# HDSC_HC32L073KATA register map
Vendor: HDSC Co.Ltd; Series: ARMCM0P; File version: 1.2
CPU: CM0 r0p0, little endian, no MPU, no FPU, 3 interrupt priority bits
Registers are 32-bit, read-write, reset 0x0 unless marked. A register's access mark holds for its fields unless they carry their own. Offsets are from the block's base; [hi:lo] are bit positions.

## RAM
Base 0x40020400
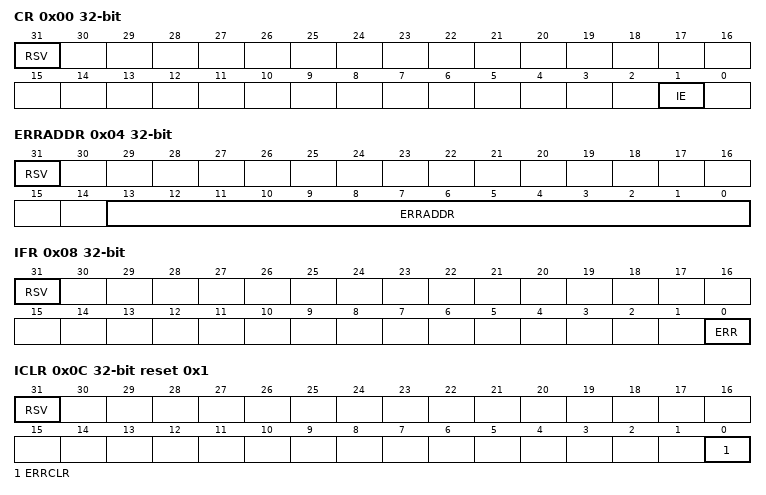
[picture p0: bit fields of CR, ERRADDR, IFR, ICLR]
0x00 CR (reset mask 0x3)
  [31] RSV, [1] IE
0x04 ERRADDR ro (reset mask 0x1FFF)
  [31] RSV rw, [13:0] ERRADDR
0x08 IFR ro (reset mask 0x1)
  [31] RSV, [0] ERR
0x0C ICLR wo reset 0x1 (reset mask 0x1)
  [31] RSV ro, [0] ERRCLR

## RESET
Base 0x4000201C
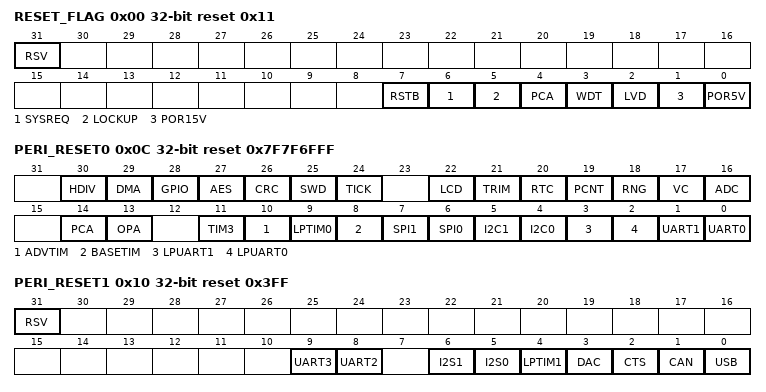
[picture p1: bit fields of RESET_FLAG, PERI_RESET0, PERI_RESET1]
0x00 RESET_FLAG reset 0x11 (reset mask 0xFF)
  [31] RSV, [7] RSTB, [6] SYSREQ, [5] LOCKUP, [4] PCA, [3] WDT, [2] LVD, [1] POR15V, [0] POR5V
0x0C PERI_RESET0 reset 0x7F7F6FFF
  [30] HDIV, [29] DMA, [28] GPIO, [27] AES, [26] CRC, [25] SWD, [24] TICK, [22] LCD, [21] TRIM, [20] RTC, [19] PCNT, [18] RNG, [17] VC, [16] ADC, [14] PCA, [13] OPA, [11] TIM3, [10] ADVTIM, [9] LPTIM0, [8] BASETIM, [7] SPI1, [6] SPI0, [5] I2C1, [4] I2C0, [3] LPUART1, [2] LPUART0, [1] UART1, [0] UART0
0x10 PERI_RESET1 reset 0x3FF (reset mask 0x3FFF)
  [31] RSV, [9] UART3, [8] UART2, [6] I2S1, [5] I2S0, [4] LPTIM1, [3] DAC, [2] CTS, [1] CAN, [0] USB

## RTC
Base 0x40001400
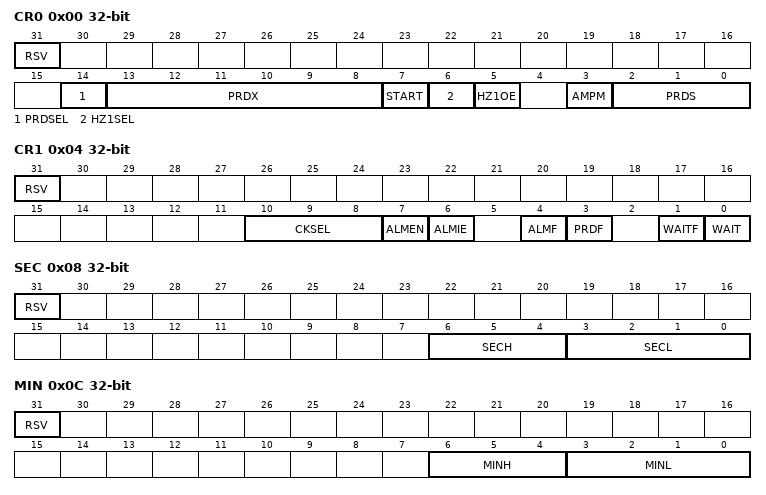
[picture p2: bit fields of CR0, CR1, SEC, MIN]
0x00 CR0 (reset mask 0x7FEF)
  [31] RSV, [14] PRDSEL, [13:8] PRDX, [7] START, [6] HZ1SEL, [5] HZ1OE, [3] AMPM, [2:0] PRDS
0x04 CR1 (reset mask 0x7FB)
  [31] RSV, [10:8] CKSEL, [7] ALMEN, [6] ALMIE, [4] ALMF, [3] PRDF, [1] WAITF, [0] WAIT
0x08 SEC (reset mask 0x7F)
  [31] RSV, [6:4] SECH, [3:0] SECL
0x0C MIN (reset mask 0x7F)
  [31] RSV, [6:4] MINH, [3:0] MINL
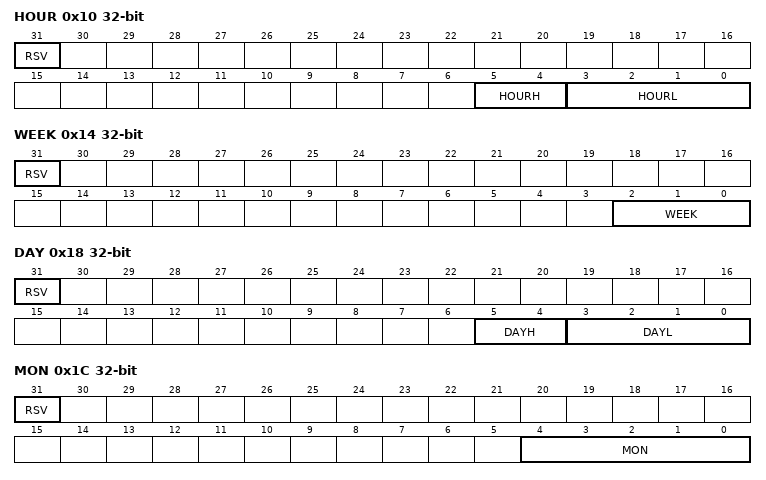
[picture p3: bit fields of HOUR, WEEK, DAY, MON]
0x10 HOUR (reset mask 0x7F)
  [31] RSV, [5:4] HOURH, [3:0] HOURL
0x14 WEEK (reset mask 0x7)
  [31] RSV, [2:0] WEEK
0x18 DAY (reset mask 0x3F)
  [31] RSV, [5:4] DAYH, [3:0] DAYL
0x1C MON (reset mask 0x1F)
  [31] RSV, [4:0] MON
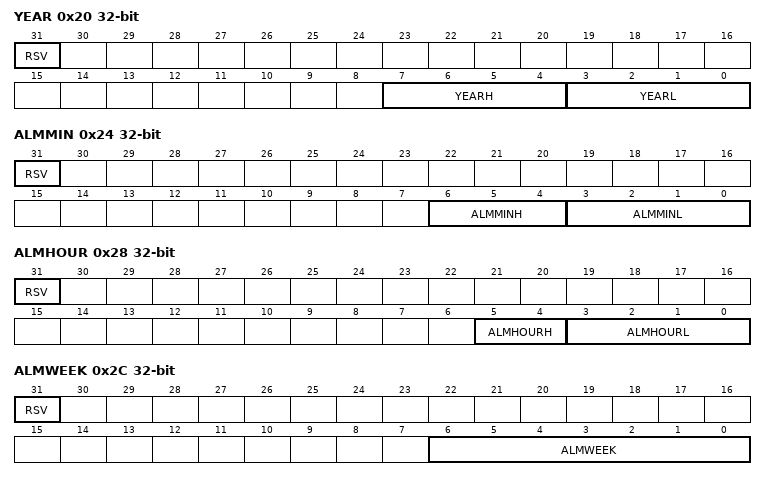
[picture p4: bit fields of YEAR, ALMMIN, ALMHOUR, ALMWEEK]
0x20 YEAR (reset mask 0xFF)
  [31] RSV, [7:4] YEARH, [3:0] YEARL
0x24 ALMMIN (reset mask 0x7F)
  [31] RSV, [6:4] ALMMINH, [3:0] ALMMINL
0x28 ALMHOUR (reset mask 0x3F)
  [31] RSV, [5:4] ALMHOURH, [3:0] ALMHOURL
0x2C ALMWEEK (reset mask 0x7F)
  [31] RSV, [6:0] ALMWEEK
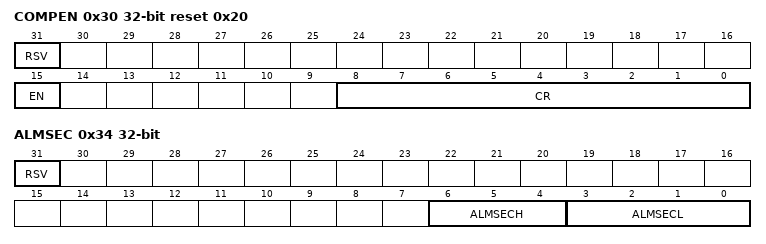
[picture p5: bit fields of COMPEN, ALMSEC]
0x30 COMPEN reset 0x20 (reset mask 0x81FF)
  [31] RSV, [15] EN, [8:0] CR
0x34 ALMSEC (reset mask 0xFF)
  [31] RSV, [6:4] ALMSECH, [3:0] ALMSECL

## SPI0 — desc SPI
Base 0x40000800
Same registers: SPI1 0x40004800
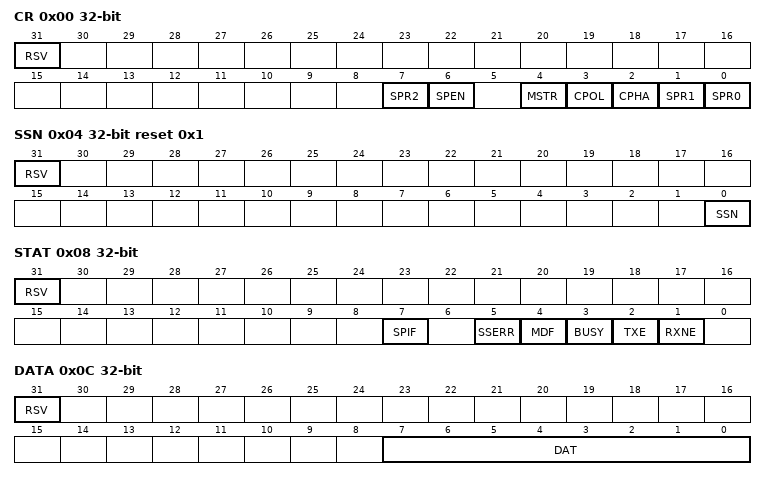
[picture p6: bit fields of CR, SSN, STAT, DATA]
0x00 CR (reset mask 0xDF)
  [31] RSV, [7] SPR2, [6] SPEN, [4] MSTR, [3] CPOL, [2] CPHA, [1] SPR1, [0] SPR0
0x04 SSN reset 0x1 (reset mask 0x1)
  [31] RSV, [0] SSN
0x08 STAT ro (reset mask 0xBE)
  [31] RSV rw, [7] SPIF, [5] SSERR, [4] MDF, [3] BUSY, [2] TXE, [1] RXNE
0x0C DATA (reset mask 0xFF)
  [31] RSV, [7:0] DAT
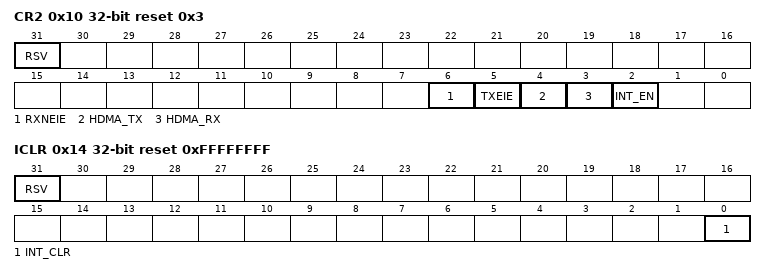
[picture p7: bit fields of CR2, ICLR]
0x10 CR2 reset 0x3 (reset mask 0x7C)
  [31] RSV, [6] RXNEIE, [5] TXEIE, [4] HDMA_TX, [3] HDMA_RX, [2] INT_EN
0x14 ICLR wo reset 0xFFFFFFFF (reset mask 0x1)
  [31] RSV rw, [0] INT_CLR

## SYSCTRL
Base 0x40002000
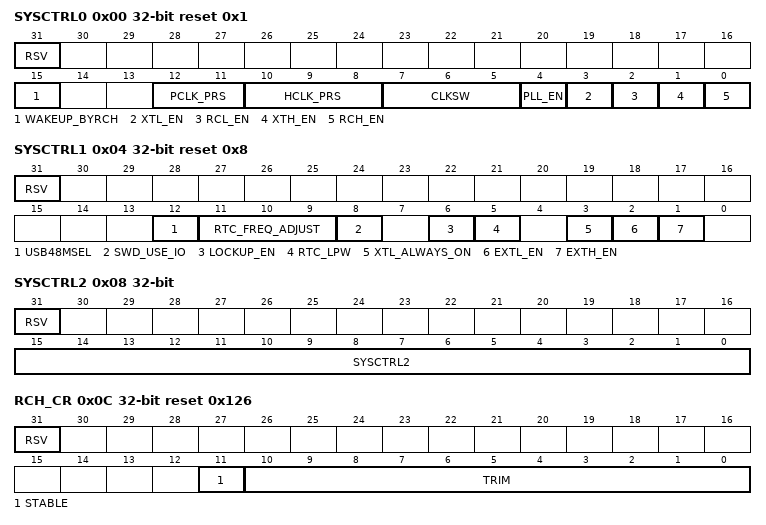
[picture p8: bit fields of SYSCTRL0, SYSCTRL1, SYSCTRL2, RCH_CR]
0x00 SYSCTRL0 reset 0x1 (reset mask 0x9FFF)
  [31] RSV, [15] WAKEUP_BYRCH, [12:11] PCLK_PRS, [10:8] HCLK_PRS, [7:5] CLKSW, [4] PLL_EN, [3] XTL_EN, [2] RCL_EN, [1] XTH_EN, [0] RCH_EN
0x04 SYSCTRL1 reset 0x8 (reset mask 0xF7E)
  [31] RSV, [12] USB48MSEL, [11:9] RTC_FREQ_ADJUST, [8] SWD_USE_IO, [6] LOCKUP_EN, [5] RTC_LPW, [3] XTL_ALWAYS_ON, [2] EXTL_EN, [1] EXTH_EN
0x08 SYSCTRL2 wo (reset mask 0xFFFF)
  [31] RSV rw, [15:0] SYSCTRL2
0x0C RCH_CR reset 0x126 (reset mask 0xFFF)
  [31] RSV, [11] STABLE ro, [10:0] TRIM
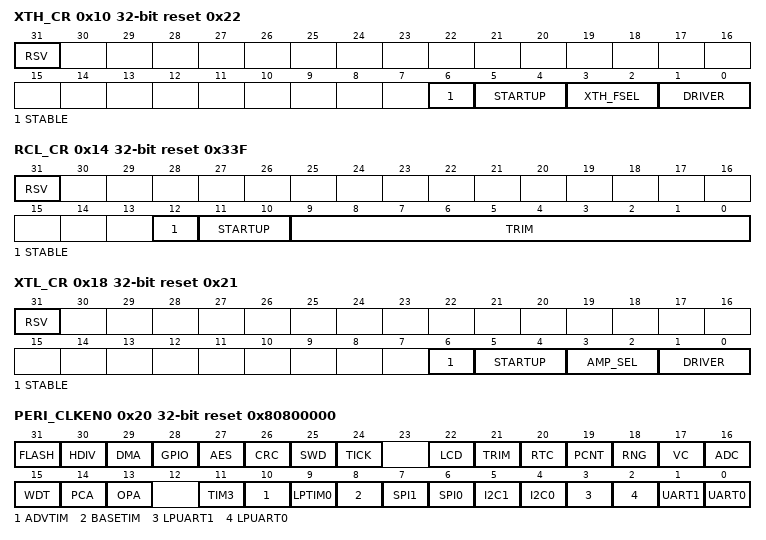
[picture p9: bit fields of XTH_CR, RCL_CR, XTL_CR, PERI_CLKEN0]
0x10 XTH_CR reset 0x22 (reset mask 0x7F)
  [31] RSV, [6] STABLE ro, [5:4] STARTUP, [3:2] XTH_FSEL, [1:0] DRIVER
0x14 RCL_CR reset 0x33F (reset mask 0x1FFF)
  [31] RSV, [12] STABLE ro, [11:10] STARTUP, [9:0] TRIM
0x18 XTL_CR reset 0x21 (reset mask 0x7F)
  [31] RSV, [6] STABLE ro, [5:4] STARTUP, [3:2] AMP_SEL, [1:0] DRIVER
0x20 PERI_CLKEN0 reset 0x80800000
  [31] FLASH, [30] HDIV, [29] DMA, [28] GPIO, [27] AES, [26] CRC, [25] SWD, [24] TICK, [22] LCD, [21] TRIM, [20] RTC, [19] PCNT, [18] RNG, [17] VC, [16] ADC, [15] WDT, [14] PCA, [13] OPA, [11] TIM3, [10] ADVTIM, [9] LPTIM0, [8] BASETIM, [7] SPI1, [6] SPI0, [5] I2C1, [4] I2C0, [3] LPUART1, [2] LPUART0, [1] UART1, [0] UART0
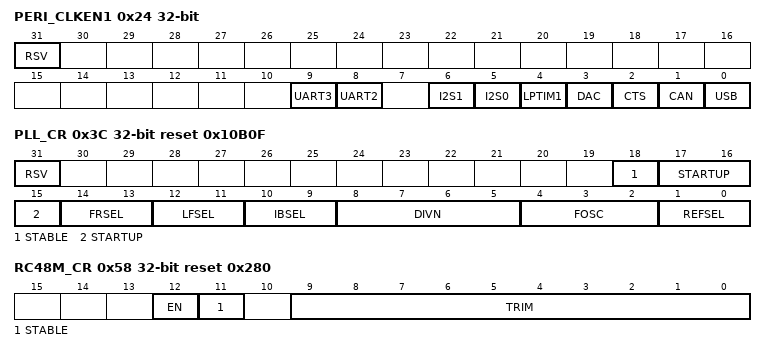
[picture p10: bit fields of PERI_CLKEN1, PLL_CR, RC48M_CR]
0x24 PERI_CLKEN1 (reset mask 0xFFF)
  [31] RSV, [9] UART3, [8] UART2, [6] I2S1, [5] I2S0, [4] LPTIM1, [3] DAC, [2] CTS, [1] CAN, [0] USB
0x3C PLL_CR reset 0x10B0F (reset mask 0x3FFFF)
  [31] RSV, [18] STABLE, [17:15] STARTUP, [14:13] FRSEL, [12:11] LFSEL, [10:9] IBSEL, [8:5] DIVN, [4:2] FOSC, [1:0] REFSEL
0x54 OVCK_CR
  [0] OVCK
0x58 RC48M_CR reset 0x280 (reset mask 0xFF)
  [12] EN, [11] STABLE ro, [9:0] TRIM
